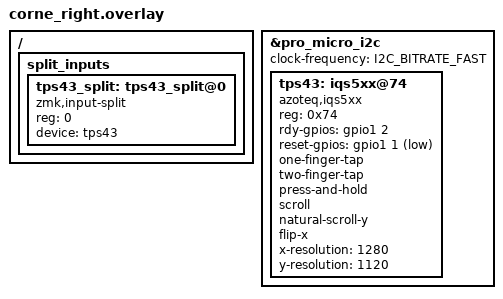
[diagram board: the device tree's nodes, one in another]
/*
 * Right half (peripheral) — touchpad hardware + split input forwarder.
 *
 * The `tps43_split` node of `zmk,input-split` intercepts raw input events
 * from the IQS5xx driver and forwards them over BLE to the central. The
 * central has a matching proxy node (same reg=0) that re-emits them for
 * its input-listener to convert to HID mouse reports.
 */

#include <zephyr/dt-bindings/i2c/i2c.h>

&pro_micro_i2c {
    status = "okay";
    clock-frequency = <I2C_BITRATE_FAST>;       /* 400kHz — chip supports Fast Mode; cuts per-event I2C time ~4x to reduce work-queue saturation */

    tps43: iqs5xx@74 {
        compatible = "azoteq,iqs5xx";
        reg = <0x74>;
        /* Pins from factory RIGHT.UF2 (flash offset 0x60ae8).
         * reset-gpios is now wired up — our AYM1607 fork bumps the
         * post-NRST-release wait from 10ms to 250ms (covers the chip's
         * ~150ms ATI period) and adds I2C retry. Combination resolves
         * the fast-power-cycle chip-state-wedge symptom that originally
         * pushed us to omit reset-gpios. */
        rdy-gpios = <&gpio1 2 GPIO_ACTIVE_HIGH>;
        reset-gpios = <&gpio1 1 GPIO_ACTIVE_LOW>;
        one-finger-tap;
        two-finger-tap;
        press-and-hold;
        scroll;
        natural-scroll-y;
        /* X-axis inversion at the chip level: writes IQS5XX_FLIP_X (BIT 0)
         * to register 0x0669 (XY_CONFIG_0) during iqs5xx_setup_device. */
        flip-x;

        /* Incremental resolution bump in chip-die-native 8:7 ratio
         * (IQS572 = 9 Rx × 8 Tx → 2048 × 1792 max → 8:7). Bump 1.25×
         * first; if chip accepts and feel is good, ladder up:
         *   1280 × 1120  (this attempt)
         *   1536 × 1344
         *   1792 × 1568
         *   2048 × 1792  (chip die max) */
        x-resolution = <1280>;
        y-resolution = <1120>;
    };
};

/ {
    split_inputs {
        #address-cells = <1>;
        #size-cells = <0>;

        tps43_split: tps43_split@0 {
            compatible = "zmk,input-split";
            reg = <0>;
            device = <&tps43>;
        };
    };
};
